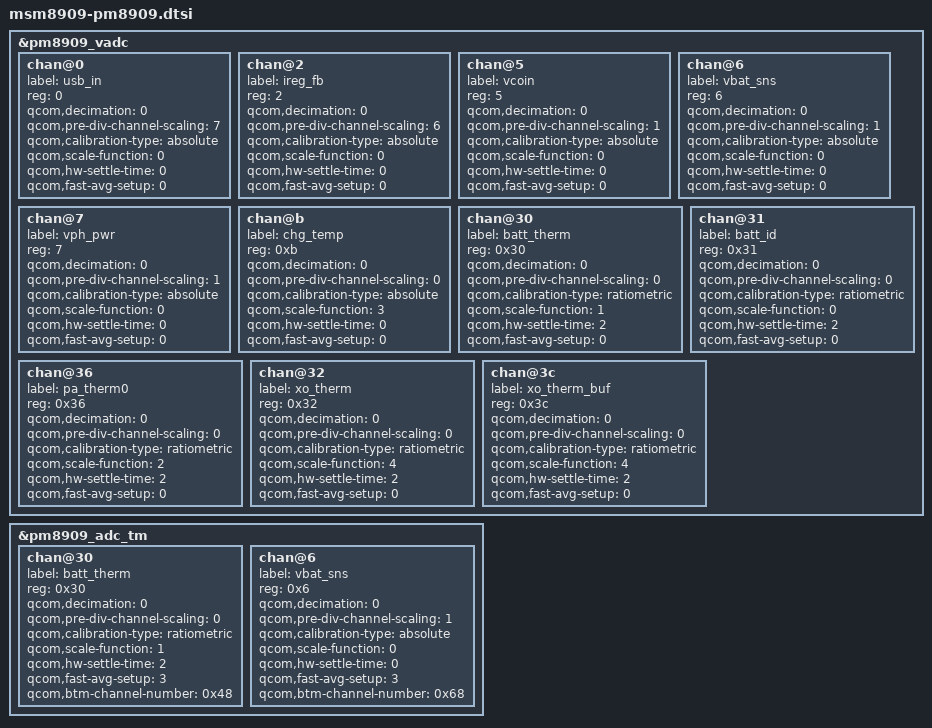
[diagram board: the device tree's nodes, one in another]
/*
 * Copyright (c) 2014, The Linux Foundation. All rights reserved.
 *
 * This program is free software; you can redistribute it and/or modify
 * it under the terms of the GNU General Public License version 2 and
 * only version 2 as published by the Free Software Foundation.
 *
 * This program is distributed in the hope that it will be useful,
 * but WITHOUT ANY WARRANTY; without even the implied warranty of
 * MERCHANTABILITY or FITNESS FOR A PARTICULAR PURPOSE.  See the
 * GNU General Public License for more details.
 */

#include "msm-pm8909-rpm-regulator.dtsi"
#include "msm-pm8909.dtsi"
#include "msm8909-regulator.dtsi"

&pm8909_vadc {
	chan@0 {
		label = "usb_in";
		reg = <0>;
		qcom,decimation = <0>;
		qcom,pre-div-channel-scaling = <7>;
		qcom,calibration-type = "absolute";
		qcom,scale-function = <0>;
		qcom,hw-settle-time = <0>;
		qcom,fast-avg-setup = <0>;
	};

	chan@2 {
		label = "ireg_fb";
		reg = <2>;
		qcom,decimation = <0>;
		qcom,pre-div-channel-scaling = <6>;
		qcom,calibration-type = "absolute";
		qcom,scale-function = <0>;
		qcom,hw-settle-time = <0>;
		qcom,fast-avg-setup = <0>;
	};

	chan@5 {
		label = "vcoin";
		reg = <5>;
		qcom,decimation = <0>;
		qcom,pre-div-channel-scaling = <1>;
		qcom,calibration-type = "absolute";
		qcom,scale-function = <0>;
		qcom,hw-settle-time = <0>;
		qcom,fast-avg-setup = <0>;
	};

	chan@6 {
		label = "vbat_sns";
		reg = <6>;
		qcom,decimation = <0>;
		qcom,pre-div-channel-scaling = <1>;
		qcom,calibration-type = "absolute";
		qcom,scale-function = <0>;
		qcom,hw-settle-time = <0>;
		qcom,fast-avg-setup = <0>;
	};

	chan@7 {
		label = "vph_pwr";
		reg = <7>;
		qcom,decimation = <0>;
		qcom,pre-div-channel-scaling = <1>;
		qcom,calibration-type = "absolute";
		qcom,scale-function = <0>;
		qcom,hw-settle-time = <0>;
		qcom,fast-avg-setup = <0>;
	};

	chan@b {
		label = "chg_temp";
		reg = <0xb>;
		qcom,decimation = <0>;
		qcom,pre-div-channel-scaling = <0>;
		qcom,calibration-type = "absolute";
		qcom,scale-function = <3>;
		qcom,hw-settle-time = <0>;
		qcom,fast-avg-setup = <0>;
	};

	chan@30 {
		label = "batt_therm";
		reg = <0x30>;
		qcom,decimation = <0>;
		qcom,pre-div-channel-scaling = <0>;
		qcom,calibration-type = "ratiometric";
		qcom,scale-function = <1>;
		qcom,hw-settle-time = <2>;
		qcom,fast-avg-setup = <0>;
	};

	chan@31 {
		label = "batt_id";
		reg = <0x31>;
		qcom,decimation = <0>;
		qcom,pre-div-channel-scaling = <0>;
		qcom,calibration-type = "ratiometric";
		qcom,scale-function = <0>;
		qcom,hw-settle-time = <2>;
		qcom,fast-avg-setup = <0>;
	};

	chan@36 {
		label = "pa_therm0";
		reg = <0x36>;
		qcom,decimation = <0>;
		qcom,pre-div-channel-scaling = <0>;
		qcom,calibration-type = "ratiometric";
		qcom,scale-function = <2>;
		qcom,hw-settle-time = <2>;
		qcom,fast-avg-setup = <0>;
	};

	chan@32 {
		label = "xo_therm";
		reg = <0x32>;
		qcom,decimation = <0>;
		qcom,pre-div-channel-scaling = <0>;
		qcom,calibration-type = "ratiometric";
		qcom,scale-function = <4>;
		qcom,hw-settle-time = <2>;
		qcom,fast-avg-setup = <0>;
	};

	chan@3c {
		label = "xo_therm_buf";
		reg = <0x3c>;
		qcom,decimation = <0>;
		qcom,pre-div-channel-scaling = <0>;
		qcom,calibration-type = "ratiometric";
		qcom,scale-function = <4>;
		qcom,hw-settle-time = <2>;
		qcom,fast-avg-setup = <0>;
	};
};

&pm8909_adc_tm {
	/* Channel Node */
	chan@30 {
		label = "batt_therm";
		reg = <0x30>;
		qcom,decimation = <0>;
		qcom,pre-div-channel-scaling = <0>;
		qcom,calibration-type = "ratiometric";
		qcom,scale-function = <1>;
		qcom,hw-settle-time = <2>;
		qcom,fast-avg-setup = <3>;
		qcom,btm-channel-number = <0x48>;
	};

	chan@6 {
		label = "vbat_sns";
		reg = <0x6>;
		qcom,decimation = <0>;
		qcom,pre-div-channel-scaling = <1>;
		qcom,calibration-type = "absolute";
		qcom,scale-function = <0>;
		qcom,hw-settle-time = <0>;
		qcom,fast-avg-setup = <3>;
		qcom,btm-channel-number = <0x68>;
	};
};

#include "msm8909-pm8909-pm.dtsi"
